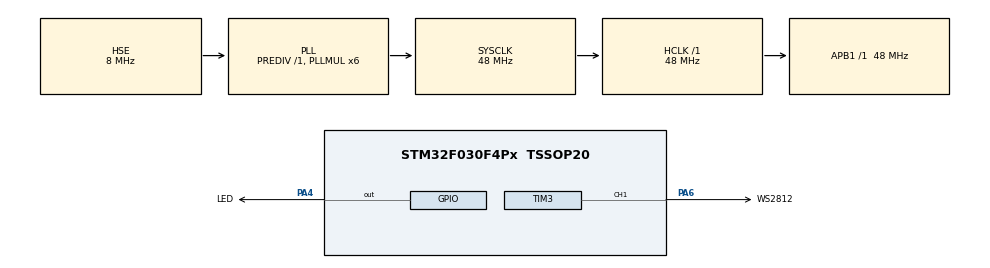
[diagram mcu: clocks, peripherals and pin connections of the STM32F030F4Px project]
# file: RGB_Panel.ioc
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Dma.Request0=TIM3_CH1/TRIG
Dma.TIM3_CH1/TRIG.0.Direction=DMA_MEMORY_TO_PERIPH
Dma.TIM3_CH1/TRIG.0.Instance=DMA1_Channel4
Dma.TIM3_CH1/TRIG.0.MemDataAlignment=DMA_MDATAALIGN_BYTE
Dma.TIM3_CH1/TRIG.0.MemInc=DMA_MINC_ENABLE
Dma.TIM3_CH1/TRIG.0.Mode=DMA_CIRCULAR
Dma.TIM3_CH1/TRIG.0.PeriphDataAlignment=DMA_PDATAALIGN_HALFWORD
Dma.TIM3_CH1/TRIG.0.PeriphInc=DMA_PINC_DISABLE
Dma.TIM3_CH1/TRIG.0.Priority=DMA_PRIORITY_VERY_HIGH
Mcu.Family=STM32F0
Mcu.Name=STM32F030F4Px
Mcu.Package=TSSOP20
NVIC.DMA1_Channel4_5_IRQn=true\:0\:0\:false\:false\:true\:false\:true
NVIC.TIM3_IRQn=true\:0\:0\:false\:false\:true\:true\:true
PA13.Mode=Serial_Wire
PA13.Signal=SYS_SWDIO
PA14.Mode=Serial_Wire
PA14.Signal=SYS_SWCLK
PA4.GPIO_Label=LED
PA4.GPIO_Speed=GPIO_SPEED_FREQ_HIGH
PA4.PinState=GPIO_PIN_SET
PA4.Signal=GPIO_Output
PA6.GPIO_Label=WS2812
PA6.GPIO_PuPd=GPIO_PULLDOWN
PA6.GPIO_Speed=GPIO_SPEED_FREQ_HIGH
PA6.Signal=S_TIM3_CH1
PF0-OSC_IN.Mode=HSE-External-Oscillator
PF0-OSC_IN.Signal=RCC_OSC_IN
PF1-OSC_OUT.Mode=HSE-External-Oscillator
PF1-OSC_OUT.Signal=RCC_OSC_OUT
ProjectManager.HeapSize=0x200
ProjectManager.StackSize=0x400
ProjectManager.TargetToolchain=MDK-ARM V5
RCC.AHBFreq_Value=48000000
RCC.APB1Freq_Value=48000000
RCC.APB1TimFreq_Value=48000000
RCC.HCLKFreq_Value=48000000
RCC.PLLMUL=RCC_PLL_MUL6
RCC.PLLSourceVirtual=RCC_PLLSOURCE_HSE
RCC.SYSCLKFreq_VALUE=48000000
RCC.SYSCLKSource=RCC_SYSCLKSOURCE_PLLCLK
SH.S_TIM3_CH1.0=TIM3_CH1,PWM Generation1 CH1
TIM3.Channel-PWM\ Generation1\ CH1=TIM_CHANNEL_1
TIM3.Period=59
TIM3.Prescaler=0
TIM3.Pulse-PWM\ Generation1\ CH1=0
VP_TIM3_VS_ClockSourceINT.Mode=Internal
board=custom

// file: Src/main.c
/* USER CODE BEGIN Header */
/**
  ******************************************************************************
  * @file           : main.c
  * @brief          : Main program body
  ******************************************************************************
  * @attention
  *
  * <h2><center>&copy; Copyright (c) 2019 STMicroelectronics.
  * All rights reserved.</center></h2>
  *
  * This software component is licensed by ST under BSD 3-Clause license,
  * the "License"; You may not use this file except in compliance with the
  * License. You may obtain a copy of the License at:
  *                        opensource.org/licenses/BSD-3-Clause
  *
  ******************************************************************************
  */
/* USER CODE END Header */

#include "main.h"
#include "dma.h"
#include "tim.h"
#include "gpio.h"

/* USER CODE BEGIN Includes */
#include "i2c.h"
#include "WS2812.h"
#include "panel_positioning.h"
/* USER CODE END Includes */

void SystemClock_Config(void);

/* USER CODE BEGIN 0 */
static uint8_t buffer[64*3] = {0};
/* USER CODE END 0 */

int main(void)
{

  /* MCU Configuration--------------------------------------------------------*/

  /* Reset of all peripherals, Initializes the Flash interface and the Systick. */
  HAL_Init();

  /* Configure the system clock */
  SystemClock_Config();

  /* Initialize all configured peripherals */
  MX_GPIO_Init();
  MX_DMA_Init();
  MX_TIM3_Init();
  /* USER CODE BEGIN 2 */
  ws2812_init();
  // MX_I2C1_Init(0x02);
  #ifdef MASTER
    HAL_Delay(25);
    startSearch_master();
  #elif defined(SLAVE)
    HAL_Delay(5);
    startDetectPanel();
  #endif
  /* USER CODE END 2 */

  /* Infinite loop */
  while (1)
  {

    /* USER CODE BEGIN 3 */
    // ws2812_fill(0, tt1, 50, 0, 0);
    // ws2812_update();
    // HAL_Delay(100);

    while(HAL_I2C_Slave_Receive(&hi2c1, buffer, 64*3, 0xFFFF) != HAL_OK);
    ws2812_fill_with_buffer(buffer);
    ws2812_update();

    // ws2812_fill(0, 64, 255, 0, 0);
    // ws2812_update();
    // HAL_Delay(500);
    // ws2812_fill(0, 64, 0, 255, 0);
    // ws2812_update();
    // HAL_Delay(500);
    // ws2812_fill(0, 64, 0, 0, 255);
    // ws2812_update();
    // HAL_Delay(500);

    // for (uint8_t i = 0; i < getOrientation() + 1; ++i) {
    //   HAL_GPIO_WritePin(LED_GPIO_Port, LED_Pin, GPIO_PIN_RESET);
    //   HAL_Delay(100);
    //   HAL_GPIO_WritePin(LED_GPIO_Port, LED_Pin, GPIO_PIN_SET);
    //   HAL_Delay(100);
    // }
    // HAL_Delay(400);

    // for (uint8_t i = 0; i < getPanelCount() + 1; ++i) {
    //   HAL_GPIO_WritePin(LED_GPIO_Port, LED_Pin, GPIO_PIN_RESET);
    //   HAL_Delay(100);
    //   HAL_GPIO_WritePin(LED_GPIO_Port, LED_Pin, GPIO_PIN_SET);
    //   HAL_Delay(100);
    // }
    // HAL_Delay(400);
  }
  /* USER CODE END 3 */
}

void SystemClock_Config(void)
{
  RCC_OscInitTypeDef RCC_OscInitStruct = {0};
  RCC_ClkInitTypeDef RCC_ClkInitStruct = {0};

  /** Initializes the CPU, AHB and APB busses clocks
  */
  RCC_OscInitStruct.OscillatorType = RCC_OSCILLATORTYPE_HSE;
  RCC_OscInitStruct.HSEState = RCC_HSE_ON;
  RCC_OscInitStruct.PLL.PLLState = RCC_PLL_ON;
  RCC_OscInitStruct.PLL.PLLSource = RCC_PLLSOURCE_HSE;
  RCC_OscInitStruct.PLL.PLLMUL = RCC_PLL_MUL6;
  RCC_OscInitStruct.PLL.PREDIV = RCC_PREDIV_DIV1;
  if (HAL_RCC_OscConfig(&RCC_OscInitStruct) != HAL_OK)
  {
    Error_Handler();
  }
  /** Initializes the CPU, AHB and APB busses clocks
  */
  RCC_ClkInitStruct.ClockType = RCC_CLOCKTYPE_HCLK|RCC_CLOCKTYPE_SYSCLK
                              |RCC_CLOCKTYPE_PCLK1;
  RCC_ClkInitStruct.SYSCLKSource = RCC_SYSCLKSOURCE_PLLCLK;
  RCC_ClkInitStruct.AHBCLKDivider = RCC_SYSCLK_DIV1;
  RCC_ClkInitStruct.APB1CLKDivider = RCC_HCLK_DIV1;

  if (HAL_RCC_ClockConfig(&RCC_ClkInitStruct, FLASH_LATENCY_1) != HAL_OK)
  {
    Error_Handler();
  }
}

void Error_Handler(void)
{
}

/************************ (C) COPYRIGHT STMicroelectronics *****END OF FILE****/
